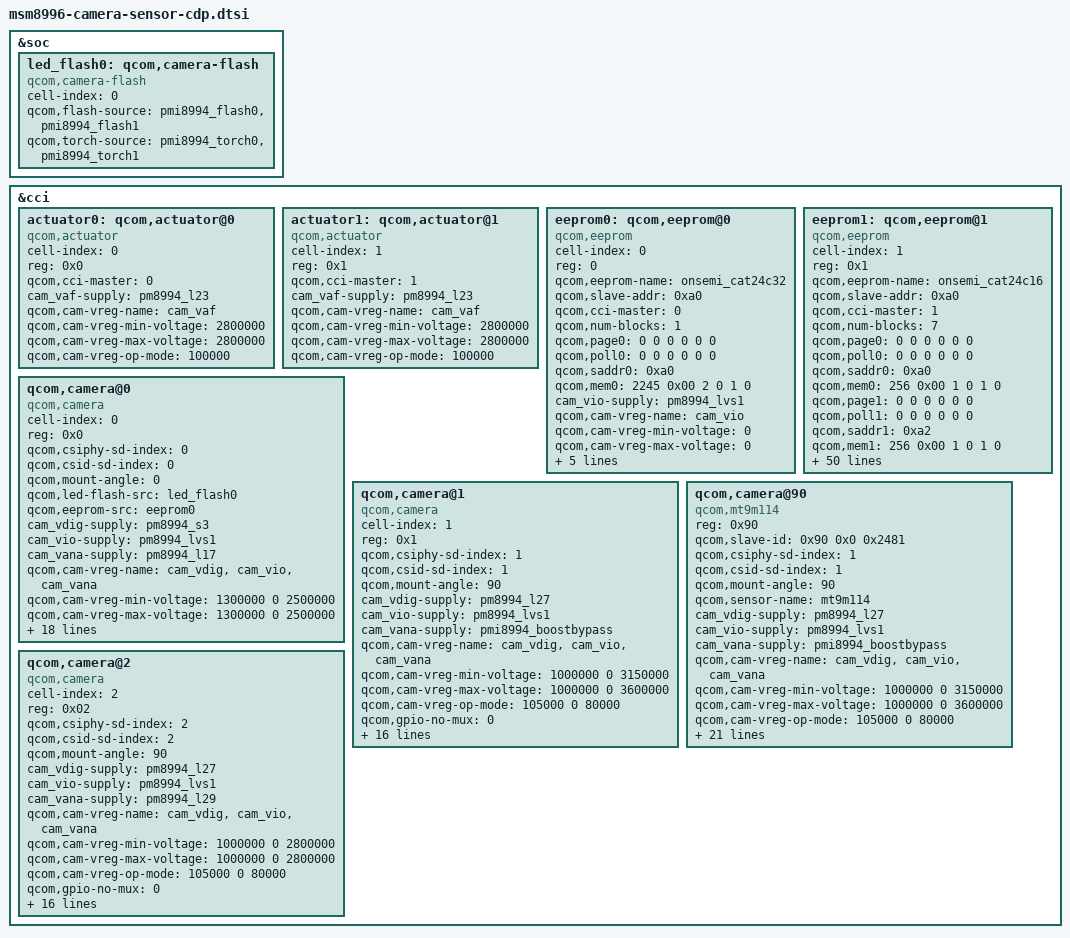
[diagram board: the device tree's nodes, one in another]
/*
 * Copyright (c) 2015 The Linux Foundation. All rights reserved.
 *
 * This program is free software; you can redistribute it and/or modify
 * it under the terms of the GNU General Public License version 2 and
 * only version 2 as published by the Free Software Foundation.
 *
 * This program is distributed in the hope that it will be useful,
 * but WITHOUT ANY WARRANTY; without even the implied warranty of
 * MERCHANTABILITY or FITNESS FOR A PARTICULAR PURPOSE.  See the
 * GNU General Public License for more details.
 */

&soc {
	led_flash0: qcom,camera-flash {
		cell-index = <0>;
		compatible = "qcom,camera-flash";
		qcom,flash-source = <&pmi8994_flash0 &pmi8994_flash1>;
		qcom,torch-source = <&pmi8994_torch0 &pmi8994_torch1>;
	};
};

&cci {
	actuator0: qcom,actuator@0 {
		cell-index = <0>;
		reg = <0x0>;
		compatible = "qcom,actuator";
		qcom,cci-master = <0>;
		cam_vaf-supply = <&pm8994_l23>;
		qcom,cam-vreg-name = "cam_vaf";
		qcom,cam-vreg-min-voltage = <2800000>;
		qcom,cam-vreg-max-voltage = <2800000>;
		qcom,cam-vreg-op-mode = <100000>;
	};

	actuator1: qcom,actuator@1 {
		cell-index = <1>;
		reg = <0x1>;
		compatible = "qcom,actuator";
		qcom,cci-master = <1>;
		cam_vaf-supply = <&pm8994_l23>;
		qcom,cam-vreg-name = "cam_vaf";
		qcom,cam-vreg-min-voltage = <2800000>;
		qcom,cam-vreg-max-voltage = <2800000>;
		qcom,cam-vreg-op-mode = <100000>;
	};

	eeprom0: qcom,eeprom@0 {
		cell-index = <0>;
		reg = <0>;
		qcom,eeprom-name = "onsemi_cat24c32";
		compatible = "qcom,eeprom";
		qcom,slave-addr = <0xa0>;
		qcom,cci-master = <0>;
		qcom,num-blocks = <1>;
		qcom,page0 = <0 0 0 0 0 0>;
		qcom,poll0 = <0 0 0 0 0 0>;
		qcom,saddr0 = <0xa0>;
		qcom,mem0 = <2245 0x00 2 0 1 0>;

		cam_vio-supply = <&pm8994_lvs1>;
		qcom,cam-vreg-name = "cam_vio";
		qcom,cam-vreg-min-voltage = <0>;
		qcom,cam-vreg-max-voltage = <0>;
		qcom,cam-vreg-op-mode = <0>;
		qcom,cam-power-seq-type = "sensor_vreg";
		qcom,cam-power-seq-val = "cam_vio";
		qcom,cam-power-seq-cfg-val = <1>;
		qcom,cam-power-seq-delay = <1>;
	};

	eeprom1: qcom,eeprom@1 {
		cell-index = <1>;
		reg = <0x1>;
		qcom,eeprom-name = "onsemi_cat24c16";
		compatible = "qcom,eeprom";
		qcom,slave-addr = <0xa0>;
		qcom,cci-master = <1>;
		qcom,num-blocks = <7>;

		qcom,page0 = <0 0 0 0 0 0>;
		qcom,poll0 = <0 0 0 0 0 0>;
		qcom,saddr0 = <0xa0>;
		qcom,mem0 = <256 0x00 1 0 1 0>;

		qcom,page1 = <0 0 0 0 0 0>;
		qcom,poll1 = <0 0 0 0 0 0>;
		qcom,saddr1 = <0xa2>;
		qcom,mem1 = <256 0x00 1 0 1 0>;

		qcom,page2 = <0 0 0 0 0 0>;
		qcom,poll2 = <0 0 0 0 0 0>;
		qcom,saddr2 = <0xa4>;
		qcom,mem2 = <256 0x00 1 0 1 0>;

		qcom,page3 = <0 0 0 0 0 0>;
		qcom,poll3 = <0 0 0 0 0 0>;
		qcom,saddr3 = <0xa6>;
		qcom,mem3 = <256 0x00 1 0 1 0>;

		qcom,page4 = <0 0 0 0 0 0>;
		qcom,poll4 = <0 0 0 0 0 0>;
		qcom,saddr4 = <0xa8>;
		qcom,mem4 = <256 0x00 1 0 1 0>;

		qcom,page5 = <0 0 0 0 0 0>;
		qcom,poll5 = <0 0 0 0 0 0>;
		qcom,saddr5 = <0xaa>;
		qcom,mem5 = <256 0x00 1 0 1 0>;

		qcom,page6 = <0 0 0 0 0 0>;
		qcom,poll6 = <0 0 0 0 0 0>;
		qcom,saddr6 = <0xac>;
		qcom,mem6 = <254 0x00 1 0 1 0>;

		cam_vdig-supply = <&pm8994_l27>;
		cam_vio-supply = <&pm8994_lvs1>;
		cam_vana-supply = <&pm8994_l29>;
		qcom,cam-vreg-name = "cam_vdig", "cam_vio", "cam_vana";
		qcom,cam-vreg-min-voltage = <1000000 0 2800000>;
		qcom,cam-vreg-max-voltage = <1000000 0 2800000>;
		qcom,cam-vreg-op-mode = <105000 0 80000>;
		qcom,gpio-no-mux = <0>;
		pinctrl-names = "cam_default", "cam_suspend";
		pinctrl-0 = <&cam_sensor_mclk2_active &cam_sensor_front_active>;
		pinctrl-1 = <&cam_sensor_mclk2_suspend &cam_sensor_front_suspend>;
		gpios = <&tlmm 15 0>,
			<&tlmm 23 0>,
			<&tlmm 26 0>;
		qcom,gpio-reset = <1>;
		qcom,gpio-standby = <2>;
		qcom,gpio-req-tbl-num = <0 1 2>;
		qcom,gpio-req-tbl-flags = <1 0 0>;
		qcom,gpio-req-tbl-label = "CAMIF_MCLK2",
					  "CAM_RESET2",
					  "CAM_STANDBY2";
		qcom,cam-power-seq-type = "sensor_vreg", "sensor_vreg", "sensor_vreg",
			"sensor_gpio", "sensor_gpio" , "sensor_clk";
		qcom,cam-power-seq-val = "cam_vdig", "cam_vana", "cam_vio",
			"sensor_gpio_reset", "sensor_gpio_standby","sensor_cam_mclk";
		qcom,cam-power-seq-cfg-val = <1 1 1 1 1 24000000>;
		qcom,cam-power-seq-delay = <1 1 1 30 30 5>;
		clocks = <&clock_mmss clk_mclk2_clk_src>,
				<&clock_mmss clk_camss_mclk2_clk>;
		clock-names = "cam_src_clk", "cam_clk";
	};

	qcom,camera@0 {
		cell-index = <0>;
		compatible = "qcom,camera";
		reg = <0x0>;
		qcom,csiphy-sd-index = <0>;
		qcom,csid-sd-index = <0>;
		qcom,mount-angle = <0>;
		qcom,led-flash-src = <&led_flash0>;
		qcom,eeprom-src = <&eeprom0>;
		cam_vdig-supply = <&pm8994_s3>;
		cam_vio-supply = <&pm8994_lvs1>;
		cam_vana-supply = <&pm8994_l17>;
		qcom,cam-vreg-name = "cam_vdig", "cam_vio", "cam_vana";
		qcom,cam-vreg-min-voltage = <1300000 0 2500000>;
		qcom,cam-vreg-max-voltage = <1300000 0 2500000>;
		qcom,cam-vreg-op-mode = <105000 0 80000>;
		qcom,gpio-no-mux = <0>;
		pinctrl-names = "cam_default", "cam_suspend";
		pinctrl-0 = <&cam_sensor_mclk0_active &cam_sensor_rear_active>;
		pinctrl-1 = <&cam_sensor_mclk0_suspend &cam_sensor_rear_suspend>;
		gpios = <&tlmm 13 0>,
			<&tlmm 30 0>,
			<&tlmm 29 0>;
		qcom,gpio-reset = <1>;
		qcom,gpio-standby = <2>;
		qcom,gpio-req-tbl-num = <0 1 2>;
		qcom,gpio-req-tbl-flags = <1 0 0>;
		qcom,gpio-req-tbl-label = "CAMIF_MCLK0",
					  "CAM_RESET0",
					  "CAM_STANDBY0";
		qcom,sensor-position = <0>;
		qcom,sensor-mode = <0>;
		qcom,cci-master = <0>;
		status = "ok";
		clocks = <&clock_mmss clk_mclk0_clk_src>,
				<&clock_mmss clk_camss_mclk0_clk>;
		clock-names = "cam_src_clk", "cam_clk";
	};

	qcom,camera@1 {
		cell-index = <1>;
		compatible = "qcom,camera";
		reg = <0x1>;
		qcom,csiphy-sd-index = <1>;
		qcom,csid-sd-index = <1>;
		qcom,mount-angle = <90>;
		cam_vdig-supply = <&pm8994_l27>;
		cam_vio-supply = <&pm8994_lvs1>;
		cam_vana-supply = <&pmi8994_boostbypass>;
		qcom,cam-vreg-name = "cam_vdig", "cam_vio", "cam_vana";
		qcom,cam-vreg-min-voltage = <1000000 0 3150000>;
		qcom,cam-vreg-max-voltage = <1000000 0 3600000>;
		qcom,cam-vreg-op-mode = <105000 0 80000>;
		qcom,gpio-no-mux = <0>;
		pinctrl-names = "cam_default", "cam_suspend";
		pinctrl-0 = <&cam_sensor_mclk1_active &cam_sensor_rear2_active>;
		pinctrl-1 = <&cam_sensor_mclk1_suspend &cam_sensor_rear2_suspend>;
		gpios = <&tlmm 14 0>,
			<&tlmm 63 0>,
			<&tlmm 62 0>;
		qcom,gpio-reset = <1>;
		qcom,gpio-standby = <2>;
		qcom,gpio-req-tbl-num = <0 1 2>;
		qcom,gpio-req-tbl-flags = <1 0 0>;
		qcom,gpio-req-tbl-label = "CAMIF_MCLK1",
					  "CAM_RESET1",
					  "CAM_STANDBY1";
		qcom,sensor-position = <0>;
		qcom,sensor-mode = <0>;
		qcom,cci-master = <0>;
		status = "ok";
		clocks = <&clock_mmss clk_mclk1_clk_src>,
			<&clock_mmss clk_camss_mclk1_clk>;
		clock-names = "cam_src_clk", "cam_clk";
	};

	qcom,camera@90 {
		compatible = "qcom,mt9m114";
		reg = <0x90>;
		qcom,slave-id = <0x90 0x0 0x2481>;
		qcom,csiphy-sd-index = <1>;
		qcom,csid-sd-index = <1>;
		qcom,mount-angle = <90>;
		qcom,sensor-name = "mt9m114";
		cam_vdig-supply = <&pm8994_l27>;
		cam_vio-supply = <&pm8994_lvs1>;
		cam_vana-supply = <&pmi8994_boostbypass>;
		qcom,cam-vreg-name = "cam_vdig", "cam_vio", "cam_vana";
		qcom,cam-vreg-min-voltage = <1000000 0 3150000>;
		qcom,cam-vreg-max-voltage = <1000000 0 3600000>;
		qcom,cam-vreg-op-mode = <105000 0 80000>;
		qcom,gpio-no-mux = <0>;
		pinctrl-names = "cam_default", "cam_suspend";
		pinctrl-0 = <&cam_sensor_mclk1_active &cam_sensor_rear2_active>;
		pinctrl-1 = <&cam_sensor_mclk1_suspend &cam_sensor_rear2_suspend>;
		gpios = <&tlmm 14 0>,
			<&tlmm 63 0>,
			<&tlmm 62 0>;
		qcom,gpio-reset = <1>;
		qcom,gpio-req-tbl-num = <0 1>;
		qcom,gpio-req-tbl-flags = <1 0>;
		qcom,gpio-req-tbl-label = "CAMIF_MCLK1",
					  "CAM_RESET1";
		qcom,gpio-set-tbl-num = <1 1>;
		qcom,gpio-set-tbl-flags = <0 2>;
		qcom,gpio-set-tbl-delay = <1000 30000>;
		qcom,csi-lane-assign = <0x4321>;
		qcom,csi-lane-mask = <0x3>;
		qcom,sensor-position = <1>;
		qcom,sensor-mode = <1>;
		qcom,cci-master = <0>;
		clocks = <&clock_mmss clk_mclk1_clk_src>,
			<&clock_mmss clk_camss_mclk1_clk>;
		clock-names = "cam_src_clk", "cam_clk";
	};

	qcom,camera@2 {
		cell-index = <2>;
		compatible = "qcom,camera";
		reg = <0x02>;
		qcom,csiphy-sd-index = <2>;
		qcom,csid-sd-index = <2>;
		qcom,mount-angle = <90>;
		cam_vdig-supply = <&pm8994_l27>;
		cam_vio-supply = <&pm8994_lvs1>;
		cam_vana-supply = <&pm8994_l29>;
		qcom,cam-vreg-name = "cam_vdig", "cam_vio", "cam_vana";
		qcom,cam-vreg-min-voltage = <1000000 0 2800000>;
		qcom,cam-vreg-max-voltage = <1000000 0 2800000>;
		qcom,cam-vreg-op-mode = <105000 0 80000>;
		qcom,gpio-no-mux = <0>;
		pinctrl-names = "cam_default", "cam_suspend";
		pinctrl-0 = <&cam_sensor_mclk2_active &cam_sensor_front_active>;
		pinctrl-1 = <&cam_sensor_mclk2_suspend &cam_sensor_front_suspend>;
		gpios = <&tlmm 15 0>,
			<&tlmm 23 0>,
			<&tlmm 26 0>;
		qcom,gpio-reset = <1>;
		qcom,gpio-standby = <2>;
		qcom,gpio-req-tbl-num = <0 1 2>;
		qcom,gpio-req-tbl-flags = <1 0 0>;
		qcom,gpio-req-tbl-label = "CAMIF_MCLK2",
					  "CAM_RESET2",
					  "CAM_STANDBY2";
		qcom,sensor-position = <1>;
		qcom,sensor-mode = <0>;
		qcom,cci-master = <1>;
		status = "ok";
		clocks = <&clock_mmss clk_mclk2_clk_src>,
			<&clock_mmss clk_camss_mclk2_clk>;
		clock-names = "cam_src_clk", "cam_clk";
	};
};
